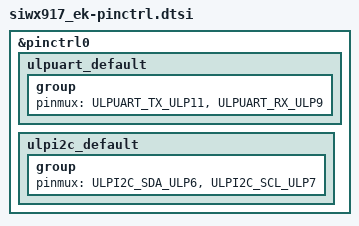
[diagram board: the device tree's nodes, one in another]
/*
 * Copyright (c) 2025 Silicon Laboratories Inc.
 * SPDX-License-Identifier: Apache-2.0
 */

#include <dt-bindings/pinctrl/silabs/siwx91x-pinctrl.h>

&pinctrl0 {
	ulpuart_default: ulpuart_default {
		group {
			pinmux = <ULPUART_TX_ULP11>, <ULPUART_RX_ULP9>;
		};
	};

	ulpi2c_default: ulpi2c_default {
		group {
			pinmux = <ULPI2C_SDA_ULP6>, <ULPI2C_SCL_ULP7>;
		};
	};
};

